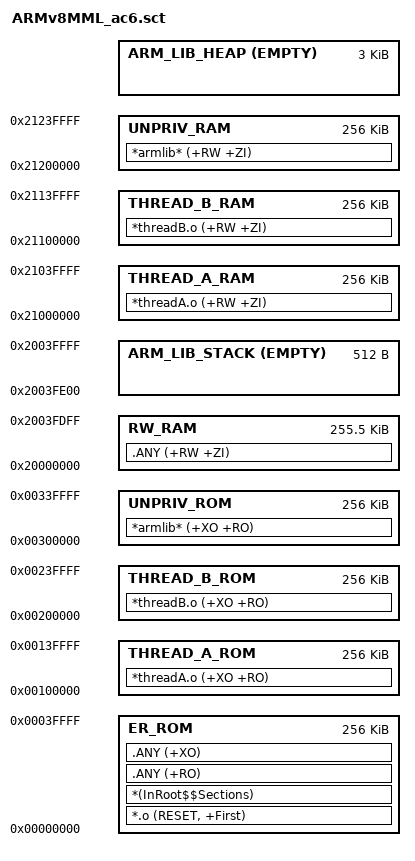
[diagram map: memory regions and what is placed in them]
#! armclang -E --target=arm-arm-none-eabi -march=armv8-m.main -xc
; command above MUST be in first line (no comment above!)
;
;/* 
; *
; * MIT License
; * Copyright (c) 2022 ARM Limited.
; * 
; * Permission is hereby granted, free of charge, to any person obtaining a copy
; * of this software and associated documentation files (the "Software"), to deal
; * in the Software without restriction, including without limitation the rights
; * to use, copy, modify, merge, publish, distribute, sublicense, and/or sell
; * copies of the Software, and to permit persons to whom the Software is
; * furnished to do so, subject to the following conditions:
; * 
; * The above copyright notice and this permission notice shall be included in all
; * copies or substantial portions of the Software.
; * 
; * THE SOFTWARE IS PROVIDED "AS IS", WITHOUT WARRANTY OF ANY KIND, EXPRESS OR
; * IMPLIED, INCLUDING BUT NOT LIMITED TO THE WARRANTIES OF MERCHANTABILITY,
; * FITNESS FOR A PARTICULAR PURPOSE AND NONINFRINGEMENT. IN NO EVENT SHALL THE
; * AUTHORS OR COPYRIGHT HOLDERS BE LIABLE FOR ANY CLAIM, DAMAGES OR OTHER
; * LIABILITY, WHETHER IN AN ACTION OF CONTRACT, TORT OR OTHERWISE, ARISING FROM,
; * OUT OF OR IN CONNECTION WITH THE SOFTWARE OR THE USE OR OTHER DEALINGS IN THE
; * SOFTWARE.
; * 
; */

#define __ROM_BASE      0x00000000
#define __ROM_SIZE      0x00040000

#define __RAM_BASE      0x20000000
#define __RAM_SIZE      0x00040000

#define __STACK_SIZE    0x00000200
#define __HEAP_SIZE     0x00000C00

#define __THREAD_A_ROM_BASE  0x00100000
#define __THREAD_A_ROM_SIZE  0x00040000

#define __THREAD_B_ROM_BASE  0x00200000
#define __THREAD_B_ROM_SIZE  0x00040000

#define __UNPRIV_ROM_BASE  0x00300000
#define __UNPRIV_ROM_SIZE  0x00040000

#define __THREAD_A_RAM_BASE  0x21000000
#define __THREAD_A_RAM_SIZE  0x00040000

#define __THREAD_B_RAM_BASE  0x21100000
#define __THREAD_B_RAM_SIZE  0x00040000

#define __UNPRIV_RAM_BASE  0x21200000
#define __UNPRIV_RAM_SIZE  0x00040000

/*----------------------------------------------------------------------------
  User Stack & Heap boundary definition
 *----------------------------------------------------------------------------*/
#define __STACK_TOP    (__RAM_BASE + __RAM_SIZE) /* starts at end of RAM */
#define __HEAP_BASE    (AlignExpr(+0, 8))        /* 8 byte aligned */


/*----------------------------------------------------------------------------
  Region base & size definition
 *----------------------------------------------------------------------------*/
#define __RO_BASE          ( __ROM_BASE )
#define __RO_SIZE          ( __ROM_SIZE )

#define __RW_BASE          ( __RAM_BASE )
#define __RW_SIZE          ( __RAM_SIZE - __STACK_SIZE )


/*----------------------------------------------------------------------------
  Scatter Region definition
 *----------------------------------------------------------------------------*/
LR_ROM __RO_BASE __RO_SIZE  {                       ; load region size_region
  
  ER_ROM __RO_BASE ALIGN 32 __RO_SIZE  {            ; load address = execution address
   *.o (RESET, +First)
   *(InRoot$$Sections)
   .ANY (+RO)
   .ANY (+XO)
  }
  
  THREAD_A_ROM __THREAD_A_ROM_BASE ALIGN 32 __THREAD_A_ROM_SIZE{
  	*threadA.o (+XO +RO)
  }
  
  
  THREAD_B_ROM __THREAD_B_ROM_BASE ALIGN 32 __THREAD_B_ROM_SIZE{
  	*threadB.o (+XO +RO)
  } 
  
  UNPRIV_ROM __UNPRIV_ROM_BASE ALIGN 32 __UNPRIV_ROM_SIZE{
  	*armlib* (+XO +RO)
  }    
  
 
  RW_RAM __RW_BASE ALIGN 32 __RW_SIZE  {                     ; RW data
   .ANY (+RW +ZI)
  }  

  ARM_LIB_STACK __STACK_TOP ALIGN 32 EMPTY -__STACK_SIZE {   ; Reserve empty region for stack
  }
  
  THREAD_A_RAM __THREAD_A_RAM_BASE ALIGN 32 __THREAD_A_RAM_SIZE{
  	*threadA.o (+RW +ZI)  	
  }  
  
  THREAD_B_RAM __THREAD_B_RAM_BASE ALIGN 32 __THREAD_B_RAM_SIZE{
  	*threadB.o (+RW +ZI)
  }    
  
  UNPRIV_RAM __UNPRIV_RAM_BASE ALIGN 32 __UNPRIV_RAM_SIZE{
  	*armlib* (+RW +ZI)
  } 
  
  #if __HEAP_SIZE > 0
  ARM_LIB_HEAP  __HEAP_BASE ALIGN 32 EMPTY  __HEAP_SIZE  {   ; Reserve empty region for heap
  }
  #endif

}
